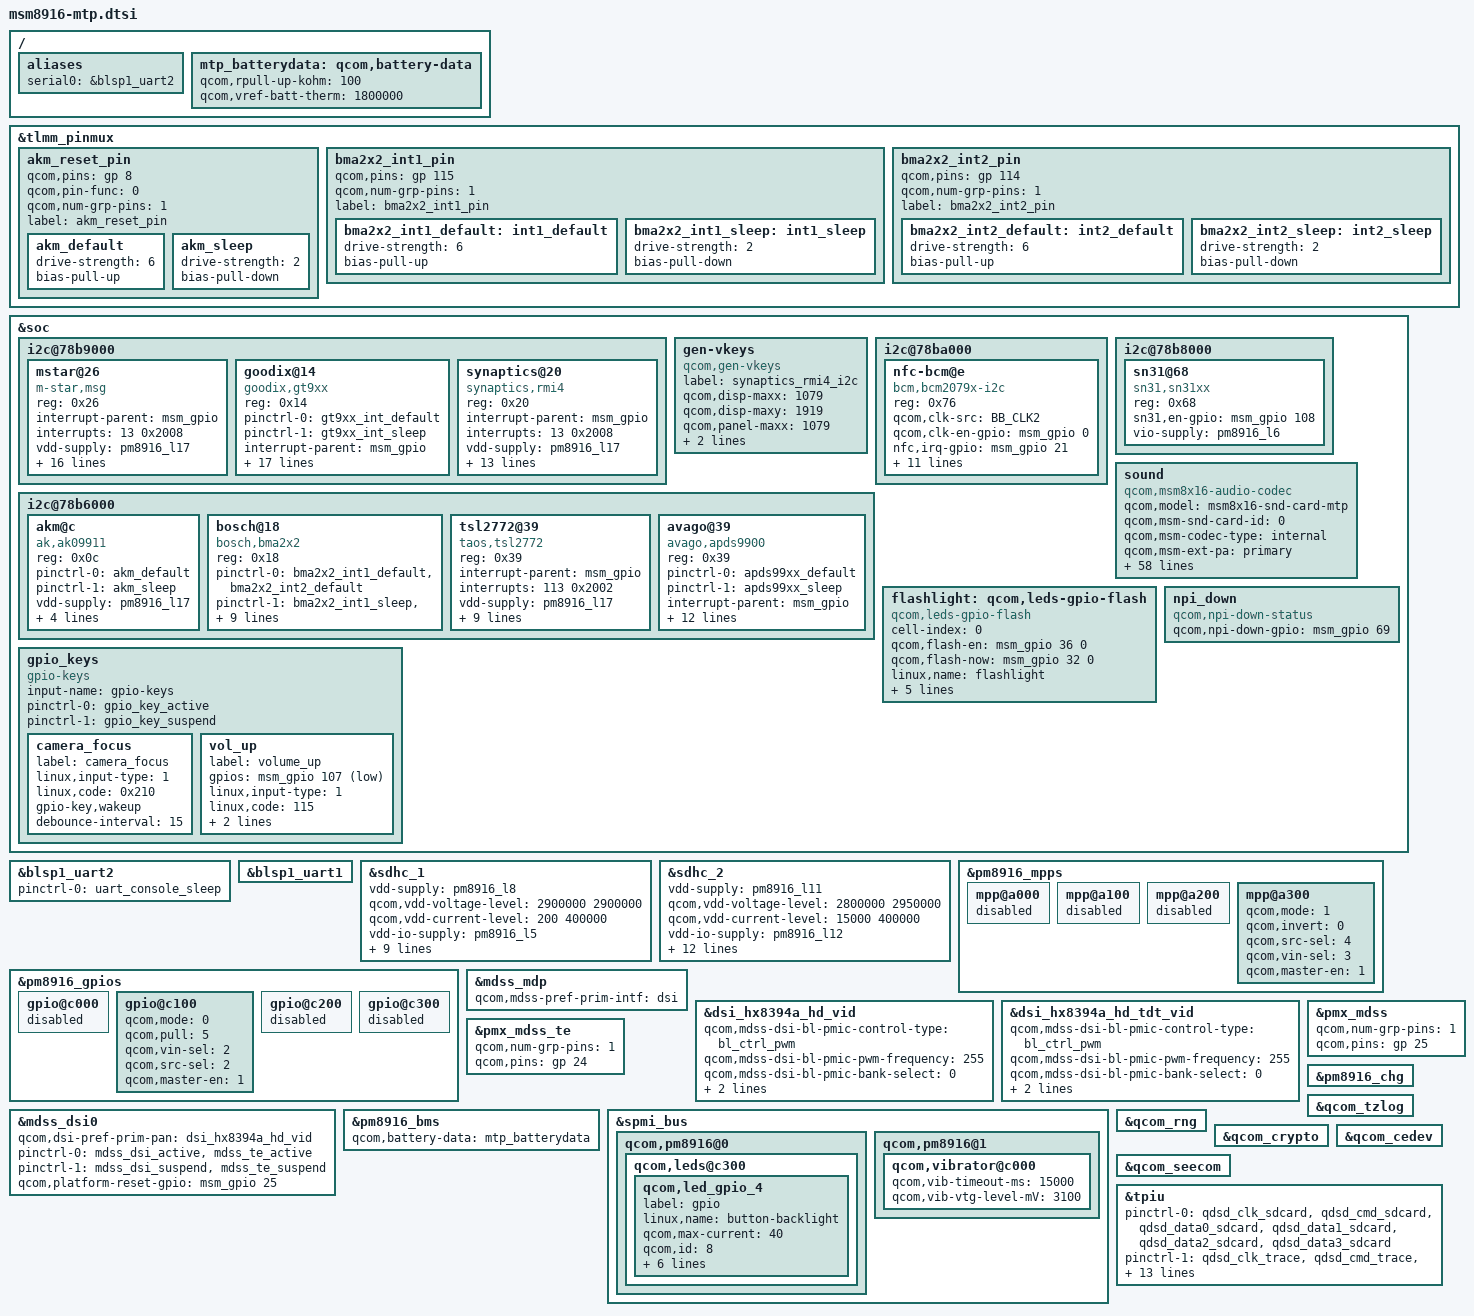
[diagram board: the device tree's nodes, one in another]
/* Copyright (c) 2014, The Linux Foundation. All rights reserved.
 *
 * This program is free software; you can redistribute it and/or modify
 * it under the terms of the GNU General Public License version 2 and
 * only version 2 as published by the Free Software Foundation.
 *
 * This program is distributed in the hope that it will be useful,
 * but WITHOUT ANY WARRANTY; without even the implied warranty of
 * MERCHANTABILITY or FITNESS FOR A PARTICULAR PURPOSE.  See the
 * GNU General Public License for more details.
 */

#include "msm8916.dtsi"
#include "msm8916-pinctrl.dtsi"
#include "msm8916-camera-sensor-mtp.dtsi"

/ {
	aliases {
		serial0 = &blsp1_uart2;
	};
};

/*  [Bug SW.Alto5_Global 724579 ] modify by xcb 2014-07-22 */
&tlmm_pinmux {
	akm_reset_pin {
		qcom,pins = <&gp 8>;
		qcom,pin-func = <0>;
		qcom,num-grp-pins = <1>;
		label = "akm_reset_pin";
		akm_default: akm_default {
			drive-strength = <6>;
			bias-pull-up;
		};
		akm_sleep: akm_sleep {
			drive-strength = <2>;
			bias-pull-down;
		};
	};


	bma2x2_int1_pin {
		qcom,pins = <&gp 115>;
		qcom,num-grp-pins = <1>;
		label = "bma2x2_int1_pin";
		bma2x2_int1_default: int1_default {
			  drive-strength = <6>;
			  bias-pull-up;
		};
		bma2x2_int1_sleep: int1_sleep {
			  drive-strength = <2>;
			  bias-pull-down;
		};
	};

	bma2x2_int2_pin {
		qcom,pins = <&gp 114>;
		qcom,num-grp-pins = <1>;
		label = "bma2x2_int2_pin";
		bma2x2_int2_default: int2_default {
			  drive-strength = <6>;
			  bias-pull-up;
		};
		bma2x2_int2_sleep: int2_sleep {
			  drive-strength = <2>;
			  bias-pull-down;
		};
	};
};
&soc {
	i2c@78b9000 { /* BLSP1 QUP5 */
	mstar@26{
			compatible = "m-star,msg";
			reg = <0x26>;
			interrupt-parent = <&msm_gpio>;
			interrupts = <13 0x2008>;
			vdd-supply = <&pm8916_l17>;
			vcc_i2c-supply = <&pm8916_l6>;
						
			mstar,name = "Mstar-TS";			
/*modify(add) by junfeng.zhou.sz for [TP driver development (1st source)] with PR721418 begin . 20140714*/			
			mstar,reset-gpios = <&msm_gpio 12 0x00>;
			mstar,interrupt-gpios = <&msm_gpio 13 0x2008>;	
			mstar,panel-coords = <0 0 540 960>;
			mstar,display-coords = <0 0 480 854>;
			mstar,button-map= <158 102 139>;
			mstar,no-force-update;
			mstar,i2c-pull-up;
			mstar,family-id = <0x0>;	

			mstar,disp-maxx = <720>;
			mstar,disp-maxy = <1280>;
/*modify(add) by junfeng.zhou.sz for [TP driver development (1st source)] with PR721418 end . */
			mstar,pan-maxx = <541>;
			mstar,pan-maxy = <1060>;
			mstar,key-codes = <158 102 139>;
			mstar,y-offset = <0>;
			/*label = "ms-msg21xx,Mstar-TS";*/
		};
/*[PLATFORM]-Add-BEGIN by TCTNB.ZXZ, FR-788135, 2014/09/25 add for FT5436 TP driver*/
		goodix@14 {
			compatible = "goodix,gt9xx";
			reg = <0x14>;

			pinctrl-names = "gt9xx_int_default","gt9xx_int_suspend";
			pinctrl-0 = <&gt9xx_int_default>;
			pinctrl-1 = <&gt9xx_int_sleep>;

			interrupt-parent = <&msm_gpio>;
			interrupts = <13 0x2008>;
			reset-gpios = <&msm_gpio 12 0x00>;
			interrupt-gpios = <&msm_gpio 13 0x00>;
                        vcc_i2c-supply = <&pm8916_l6>;
			avdd-supply =<&pm8916_l17>;/* <&tp_power>;*/
                        vdd-supply = <&pm8916_l17>;
			goodix,panel-coords =<0 0 720 1400>;
			goodix,display-coords = <0 0 720 1280>;
			goodix,button-map= <158 102 139>;
                        regulator-min-microvolt = <2800000>;
                        regulator-max-microvolt = <2800000>;
			goodix,family-id = <0x0>;
                        goodix,i2c-pull-up;
                        /*baoming TP config,Id=1*/
                       /*Modify by TCTNB Tianhongwei update config, version v67*/
                      goodix,cfg-data0 = [
				43 D0 02 00 05 05 35 05 01 C5 28 18 46 2D 03 05 00 00 00 02 03 00 00 14 14 1B 14 8A 09 0B 62 00 29 07 40 08
				00 01 33 11 32 11 00 00 00 10 00 32 00 00 19 32 82 94 C5 02 00 00 00 04 C6 37 00 A5 42 00 85 50 00 6C 62 00
				59 76 00 59 10 30 50 00 F7 45 35 33 33 27 00 00 00 00 00 00 00 00 00 00 00 00 00 00 00 00 00 00 00 00 00 19
				00 00 46 00 02 04 06 08 0A 0C 0E 10 12 14 16 FF FF FF 00 00 00 00 00 00 00 00 00 00 00 00 00 00	00 00 22 21
				20 1F 1E 1D 1C 18 16 12 10 0F 0C 0A 08 06 04 02 00 FF FF FF FF FF FF FF 00 00 00 4F FF FF FF FF FF FF FF 4F
				FF FF FF FF 51 01
				];
		      goodix,glove-cfg-data1 = [
				43 D0 02 00 05 05 34 11 01 08 28 0F 55 3C 03 05 00 00 00 00 10 04 00 14 15 1E 14 8C 2E 0E 37 3A B8 08 B8 08
				00 84 34 1D 00 14 08 03 14 03 64 32 00 00 1B 23 5A 94 C0 02 00 00 77 04 A3 26 00 8F 2E 00 7E 38 00 71 44 00
				67 52 00 67 18 40 60 00 57 50 40 EE E0 27 00 01 11 03 3C 32 00 00 FF 7F 00 00 00 00 00 00 00 00 00 19 4B 3C
				32 00 00 00 02 04 06 08 0A 0C 0E 10 12 14 16 18 1A 1C 00 00 00 00 00 00 00 00 00 00 00 00 00 00 00 00 2A 29
				28 26 24 22 21 20 1F 1E 1D 1C 18 16 14 13 12 10 0F 0C 0A 08 06 04 02 00 00 00 00 00 00 00 00 00 00 00 00 00
				00 00 00 00 F9 01
			];

		};
/*[PLATFORM]-Add-BEGIN by TCTNB.ZXZ*/
		synaptics@20 {
			compatible = "synaptics,rmi4";
			reg = <0x20>;
			interrupt-parent = <&msm_gpio>;
			interrupts = <13 0x2008>;
			vdd-supply = <&pm8916_l17>;
			vcc_i2c-supply = <&pm8916_l6>;
			/* pins used by touchscreen */
			pinctrl-names = "pmx_ts_active","pmx_ts_suspend","pmx_ts_suspend";
			pinctrl-0 = <&ts_int_active &ts_reset_active>;
			pinctrl-1 = <&ts_int_suspend &ts_reset_suspend>;
			pinctrl-2 = <&ts_release>;
			synaptics,display-coords = <0 0 1079 1919>;
			synaptics,panel-coords = <0 0 1079 2084>;
			synaptics,irq-gpio = <&msm_gpio 13 0x2008>;
			synaptics,reset-gpio = <&msm_gpio 12 0x0>;
			synaptics,i2c-pull-up;
			synaptics,power-down;
			synaptics,disable-gpios;
			/* Underlying clocks used by secure touch */
			clocks = <&clock_gcc clk_gcc_blsp1_ahb_clk>,
			 <&clock_gcc clk_gcc_blsp1_qup5_i2c_apps_clk>;
			clock-names = "iface_clk", "core_clk";
		};
	};

	gen-vkeys {
		compatible = "qcom,gen-vkeys";
		label = "synaptics_rmi4_i2c";
		qcom,disp-maxx = <1079>;
		qcom,disp-maxy = <1919>;
		qcom,panel-maxx = <1079>;
		qcom,panel-maxy = <2084>;
		qcom,key-codes = <158 139 172 217>;
	};

	i2c@78ba000 { /* BLSP1 QUP6 */
		nfc-bcm@e {/*modify by jch for NFC driver development*/
			compatible = "bcm,bcm2079x-i2c";/*modify by jch for NFC driver development*/
			reg = <0x76>;/*modify by jch for NFC driver development*/
/*
			qcom,irq-gpio = <&msm_gpio 21 0x00>;
			qcom,dis-gpio = <&msm_gpio 20 0x00>;
*/
			qcom,clk-src = "BB_CLK2";/*modify by jch for NFC driver development*/
			qcom,clk-en-gpio = <&msm_gpio 0 0x00>;/*modify by jch for NFC driver development*/
/*begin add by jch for NFC driver development*/
                        nfc,irq-gpio = <&msm_gpio 21 0x00>;
			nfc,wake_gpio = <&msm_gpio 20 0x00>;
			nfc,en-gpio = <&msm_gpio 31 0x00>;
                        nfc,clk-gpio = <&pm8916_gpios 2 0>;
                        /*comment this for cannot find SIM Card issue*/
                        /*uim-supply = <&pm8916_l14>;*/
/*end add by jch for NFC driver development*/
			interrupt-parent = <&msm_gpio>;
			interrupts = <21 0>;
                        vi2c-supply = <&pm8916_l5>;/*add by jch for NFC driver development*/
			interrupt-names = "nfc_irq";
			pinctrl-names = "nfc_active","nfc_suspend";
			pinctrl-0 = <&nfc_int_active &nfc_disable_active>;
			pinctrl-1 = <&nfc_int_suspend &nfc_disable_suspend>;
			qcom,clk-gpio = <&pm8916_gpios 2 0>;/* [BUFFIX]-Mod- by TCTNB.XQJ, PR-804255, 2014/10/29,add nfc clock control*/
			clocks = <&clock_rpm clk_bb_clk2_pin>;
			clock-names = "ref_clk";
		};
	};

	i2c@78b6000 { /* BLSP1 QUP2 */
		akm@c {
			compatible = "ak,ak09911";
			reg = <0x0c>;
			pinctrl-names = "default","sleep";
			pinctrl-0 = <&akm_default>;
			pinctrl-1 = <&akm_sleep>;
			vdd-supply = <&pm8916_l17>;
			vio-supply = <&pm8916_l6>;
			akm,layout = <0x3>;
			akm,gpio_rstn = <&msm_gpio 8 0x0>;
			akm,auto-report;
		};
	    bosch@18 { /* Accelerometer sensor [Bug SW.Alto5_Global 724579 ] modify by xcb 2014-07-22 */
	        compatible = "bosch,bma2x2";
	        reg = <0x18>;
	        pinctrl-names = "bma_default","bma_sleep";
	        pinctrl-0 = <&bma2x2_int1_default &bma2x2_int2_default>;
	        pinctrl-1 = <&bma2x2_int1_sleep &bma2x2_int2_sleep>;
	        interrupt-parent = <&msm_gpio>;
	        interrupts = <115 0x2002>;
	        vdd-supply = <&pm8916_l6>;
	        vio-supply = <&pm8916_l6>;
	        bosch,init-interval = <200>;
	        bosch,place = <2>;
	        bosch,gpio-int1 = <&msm_gpio 115 0x2002>;
	        bosch,gpio-int2 = <&msm_gpio 114 0x2002>;
	    };

		/*yongzhong.cheng,2014/07/24,PR 724584: add proximity and light sensor config begin*/
                tsl2772@39 {
                    compatible = "taos,tsl2772";
                        reg = <0x39>;
                        interrupt-parent = <&msm_gpio>;
                        interrupts = <113 0x2002>;
                        vdd-supply = <&pm8916_l17>;
                        vio-supply = <&pm8916_l6>;
                        tsl,irq-gpio = <&msm_gpio 113 0x2002>;
                        tsl,als-gate = <10>;    //
                        tsl,als-gain = <8>;     //
			tsl,control-reg = <0x25>; /* [BUFFIX]-Mod- by TCTNB.XQJ, PR-804886, 2014/10/23, p sensor debug*/
			tsl,wait-reg = <0x00>;
			tsl,ps-thdh = <950>;
			tsl,ps-thdl = <900>;
			tsl,ps-ppcount = <16>; /* [BUFFIX]-Mod- by yuzhong.li@tcl.com, PR-929456, 2015/3/2, p sensor debug*/
		};
                /*yongzhong.cheng,2014/07/24,PR 724584: add proximity and light sensor config end*/
		avago@39 { /* Ambient light and proximity sensor */
			compatible = "avago,apds9900";
			reg = <0x39>;
			pinctrl-names = "default","sleep";
			pinctrl-0 = <&apds99xx_default>;
			pinctrl-1 = <&apds99xx_sleep>;
			interrupt-parent = <&msm_gpio>;
			interrupts = <113 0x2002>;
			vdd-supply = <&pm8916_l17>;
			vio-supply = <&pm8916_l6>;
			avago,irq-gpio = <&msm_gpio 113 0x2002>;
			avago,ps-threshold = <600>;
			avago,ps-hysteresis-threshold = <500>;
			avago,ps-pulse = <8>;
			avago,ps-pgain = <0>;
			avago,als-B = <223>;
			avago,als-C = <70>;
			avago,als-D = <142>;
			avago,ga-value = <48>;
		};


	};
/* [PLATFORM]-Add-BEGIN by TCTNB.FLF, RR-813549, 2014/10/18, add sn31 for alto5 global */
	i2c@78b8000 { /* BLSP1 QUP2 */
        sn31@68{
              compatible = "sn31,sn31xx";
              reg = <0x68>;
              //pinctrl-names = "default";
              sn31,en-gpio = <&msm_gpio 108 0x00>; /*[BUGFIX]-add  by TCTNB.XQJ,PR-803287 2014/10/23,add  led ic sn31xx,gpio is used for led ic*/
              vio-supply = <&pm8916_l6>;
		};
	};
/* [PLATFORM]-Add-END by TCTNB.FLF */

	sound {
		compatible = "qcom,msm8x16-audio-codec";
		qcom,model = "msm8x16-snd-card-mtp";
		qcom,msm-snd-card-id = <0>;
		qcom,msm-codec-type = "internal";
		qcom,msm-ext-pa = "primary";
		qcom,msm-mclk-freq = <9600000>;
/* [PLATFORM]-Mod-BEGIN by TCTNB.HJ, 2014/10/17*/
		qcom,msm-mbhc-hphl-swh = <1>;
/* [PLATFORM]-Mod-END by TCTNB.HJ, 2014/10/17*/
		qcom,msm-mbhc-gnd-swh = <0>;
		qcom,msm-micbias1-ext-cap;
		qcom,msm-hs-micbias-type = "internal";
		qcom,audio-routing =
			"RX_BIAS", "MCLK",
			"SPK_RX_BIAS", "MCLK",
			"INT_LDO_H", "MCLK",
			"MIC BIAS External", "Handset Mic",
			"MIC BIAS Internal2", "Headset Mic",
			"MIC BIAS External", "Secondary Mic",
			"AMIC1", "MIC BIAS External",
			"AMIC2", "MIC BIAS Internal2",
			"AMIC3", "MIC BIAS External",
			"DMIC1", "MIC BIAS Internal1",
			"MIC BIAS Internal1", "Digital Mic1",
			"DMIC2", "MIC BIAS Internal1",
			"MIC BIAS Internal1", "Digital Mic2";
		pinctrl-names = "cdc_lines_act",
				"cdc_lines_sus",
				"cdc_lines_sec_ext_act",
				"cdc_lines_sec_ext_sus",
				"cross_conn_det_act",
				"cross_conn_det_sus";
		pinctrl-0 = <&cdc_pdm_lines_act>;
		pinctrl-1 = <&cdc_pdm_lines_sus>;
		pinctrl-2 = <&cdc_pdm_lines_act &cdc_ext_pa_act
						&cdc_ext_pa_ws_act>;
		pinctrl-3 = <&cdc_pdm_lines_sus &cdc_ext_pa_sus
						&cdc_ext_pa_ws_sus>;
		pinctrl-4 = <&cross_conn_det_act>;
		pinctrl-5 = <&cross_conn_det_sus>;
		qcom,cdc-us-euro-gpios = <&msm_gpio 120 0>;
		asoc-platform = <&pcm0>, <&pcm1>, <&voip>, <&voice>,
				<&loopback>, <&compress>, <&hostless>,
				<&afe>, <&lsm>, <&routing>, <&lpa>;
		asoc-platform-names = "msm-pcm-dsp.0", "msm-pcm-dsp.1",
				"msm-voip-dsp", "msm-pcm-voice", "msm-pcm-loopback",
				"msm-compress-dsp", "msm-pcm-hostless", "msm-pcm-afe",
				"msm-lsm-client", "msm-pcm-routing", "msm-pcm-lpa";
		asoc-cpu = <&dai_pri_auxpcm>, <&dai_hdmi>,
				<&dai_mi2s0>, <&dai_mi2s1>, <&dai_mi2s2>, <&dai_mi2s3>,
				<&sb_0_rx>, <&sb_0_tx>, <&sb_1_rx>, <&sb_1_tx>,
				<&sb_3_rx>, <&sb_3_tx>, <&sb_4_rx>, <&sb_4_tx>,
				<&bt_sco_rx>, <&bt_sco_tx>, <&int_fm_rx>, <&int_fm_tx>,
				<&afe_pcm_rx>, <&afe_pcm_tx>, <&afe_proxy_rx>, <&afe_proxy_tx>,
				<&incall_record_rx>, <&incall_record_tx>, <&incall_music_rx>,
				<&incall_music_2_rx>;
		asoc-cpu-names = "msm-dai-q6-auxpcm.1", "msm-dai-q6-hdmi.8",
				"msm-dai-q6-mi2s.0", "msm-dai-q6-mi2s.1",
				"msm-dai-q6-mi2s.2", "msm-dai-q6-mi2s.3",
				"msm-dai-q6-dev.16384", "msm-dai-q6-dev.16385",
				"msm-dai-q6-dev.16386", "msm-dai-q6-dev.16387",
				"msm-dai-q6-dev.16390", "msm-dai-q6-dev.16391",
				"msm-dai-q6-dev.16392", "msm-dai-q6-dev.16393",
				"msm-dai-q6-dev.12288", "msm-dai-q6-dev.12289",
				"msm-dai-q6-dev.12292", "msm-dai-q6-dev.12293",
				"msm-dai-q6-dev.224", "msm-dai-q6-dev.225",
				"msm-dai-q6-dev.241", "msm-dai-q6-dev.240",
				"msm-dai-q6-dev.32771", "msm-dai-q6-dev.32772",
				"msm-dai-q6-dev.32773", "msm-dai-q6-dev.32770";
		asoc-codec = <&stub_codec>, <&pm8916_tombak_dig>;
		asoc-codec-names = "msm-stub-codec.1", "tombak_codec";
	};
};

&blsp1_uart2 {
	status = "ok";
	pinctrl-names = "default";
	pinctrl-0 = <&uart_console_sleep>;
};

&soc {

	flashlight: qcom,leds-gpio-flash{
		cell-index = <0>;
		compatible = "qcom,leds-gpio-flash";
		status = "okay";
		qcom,flash-en = <&msm_gpio 36 0>;
		qcom,flash-now = <&msm_gpio 32 0>;
		linux,name = "flashlight";
		linux,default-trigger = "flashlight-trigger";
		qcom,current = <255>;
/* [PLATFORM]-Add-BEGIN by TCTNB.qijiang.yu, 2014/05/13, flash enable use gp_clk */
		clocks = <&clock_gcc clk_gcc_camss_gp1_clk>;
		clock-names = "cam_sensor_flash";

		pinctrl-names = "default", "sleep";
/*
		pinctrl-0 = <&ice40_infrared_default>;
		pinctrl-1 = <&ice40_infrared_sleep>;
*/
		pinctrl-0 = <&cam_sensor_flash_default>;
		pinctrl-1 = <&cam_sensor_flash_sleep>;
/* [PLATFORM]-Add-END by TCTNB.qijiang.yu */
	};
/* [PLATFORM]-Add-END by TCTNB.Alvin */
	gpio_keys {
		compatible = "gpio-keys";
		input-name = "gpio-keys";
		pinctrl-names = "tlmm_gpio_key_active","tlmm_gpio_key_suspend";
		pinctrl-0 = <&gpio_key_active>;
		pinctrl-1 = <&gpio_key_suspend>;

		camera_focus {
			label = "camera_focus";
			//gpios = <&msm_gpio 108 0x1>;/*[BUGFIX]-del   by TCTNB.XQJ,PR-803287 2014/10/23,add 2nd led ic sn31xx,gpio is used for led ic*/
			linux,input-type = <1>;
			linux,code = <0x210>;
			gpio-key,wakeup;
			debounce-interval = <15>;
		};
/*
		camera_snapshot {
			label = "camera_snapshot";
			gpios = <&msm_gpio 109 0x1>;
			linux,input-type = <1>;
			linux,code = <0x2fe>;
			gpio-key,wakeup;
			debounce-interval = <15>;
		};
*/
		vol_up {
			label = "volume_up";
			gpios = <&msm_gpio 107 0x1>;
			linux,input-type = <1>;
			linux,code = <115>;
			gpio-key,wakeup;
			debounce-interval = <15>;
		};
	};
/* [PLATFORM]-Add-BEGIN by TCTNB.ZXZ, 2014/12/13,FR853499 add for npi down status gpio */
	npi_down{
			compatible = "qcom,npi-down-status";
			qcom,npi-down-gpio = <&msm_gpio 69 0>;
		};
/* [PLATFORM]-Add-END by TCTNB.ZXZ */
};

&blsp1_uart1 {
	status = "ok";
};

&sdhc_1 {
	vdd-supply = <&pm8916_l8>;
	qcom,vdd-voltage-level = <2900000 2900000>;
	qcom,vdd-current-level = <200 400000>;

	vdd-io-supply = <&pm8916_l5>;
	qcom,vdd-io-always-on;
	qcom,vdd-io-lpm-sup;
	qcom,vdd-io-voltage-level = <1800000 1800000>;
	qcom,vdd-io-current-level = <200 60000>;

	pinctrl-names = "active", "sleep";
	pinctrl-0 = <&sdc1_clk_on &sdc1_cmd_on &sdc1_data_on>;
	pinctrl-1 = <&sdc1_clk_off &sdc1_cmd_off &sdc1_data_off>;

	qcom,nonremovable;

	status = "ok";
};

&sdhc_2 {
	vdd-supply = <&pm8916_l11>;
	qcom,vdd-voltage-level = <2800000 2950000>;
	qcom,vdd-current-level = <15000 400000>;

	vdd-io-supply = <&pm8916_l12>;
	qcom,vdd-io-voltage-level = <1800000 2950000>;
	qcom,vdd-io-current-level = <200 50000>;

	pinctrl-names = "active", "sleep";
	pinctrl-0 = <&sdc2_clk_on &sdc2_cmd_on &sdc2_data_on &sdc2_cd_on>;
	pinctrl-1 = <&sdc2_clk_off &sdc2_cmd_off &sdc2_data_off &sdc2_cd_off>;

	#address-cells = <0>;
	interrupt-parent = <&sdhc_2>;
	interrupts = <0 1 2>;
	#interrupt-cells = <1>;
	interrupt-map-mask = <0xffffffff>;
	interrupt-map = <0 &intc 0 125 0
			1 &intc 0 221 0
			2 &msm_gpio 38 0>;
	interrupt-names = "hc_irq", "pwr_irq", "status_irq";
	cd-gpios = <&msm_gpio 38 0x0>;  /* modify by shenghua.gong@tcl.com for sd card detect */

	status = "ok";
};

&pm8916_mpps {
	mpp@a000 { /* MPP 1 */
		/* VDD_PX */
		status = "disabled";
	};

	mpp@a100 { /* MPP 2 */
		/* HR LED */
		status = "disabled";
	};

	mpp@a200 { /* MPP 3 */
		/* VREF DAC */
		status = "disabled";
	};

	mpp@a300 { /* MPP 4 */
		/* Backlight PWM */
		qcom,mode = <1>;		/* Digital output */
		qcom,invert = <0>;		/* Disable invert */
		qcom,src-sel = <4>;		/* DTEST1 */
		qcom,vin-sel = <3>;		/* VPH_PWR */
		qcom,master-en = <1>;		/* Enable MPP */
	};
};

&pm8916_gpios {
	gpio@c000 { /* GPIO 1 */
		/* Battery UICC Alarm */
		status = "disabled";
	};

	gpio@c100 { /* GPIO 2 */
		/* NFC_CLK_REQ */
		qcom,mode = <0>; /* QPNP_PIN_MODE_DIG_IN */
		qcom,pull = <5>; /* QPNP_PIN_PULL_NO */
		qcom,vin-sel = <2>; /* QPNP_PIN_VIN2 */
		qcom,src-sel = <2>; /* QPNP_PIN_SEL_FUNC_1 */
		qcom,master-en = <1>;
	};

	gpio@c200 { /* GPIO 3 */
		/* External regulator control for WTR */
		status = "disabled";
	};

	gpio@c300 { /* GPIO 4 */
		/* External regulator control for APC */
		status = "disabled";
	};
};

/* [PLATFORM] TCTNB.THW, FR-623588, 2014/09/19, Alto5_VDF 1st lcd */
#include "dsi-panel-hx8394a-hd-truly-video.dtsi"
/* [PLATFORM] TCTNB.THW, FR-623588, 2014/09/23, Alto5_VDF 2st lcd */
#include "dsi-panel-hx8394a-hd-tdt-video.dtsi"

&mdss_mdp {
	qcom,mdss-pref-prim-intf = "dsi";
};

&dsi_hx8394a_hd_vid {
/* [PLATFORM]-Add-END by TCTNB.FLF */
	qcom,mdss-dsi-bl-pmic-control-type = "bl_ctrl_pwm";
	qcom,mdss-dsi-bl-pmic-pwm-frequency = <255>;
	qcom,mdss-dsi-bl-pmic-bank-select = <0>;
	qcom,mdss-dsi-pwm-gpio = <&pm8916_mpps 4 0>;
	qcom,cont-splash-enabled;
};

/* [PLATFORM] TCTNB.THW, FR-623588, 2014/09/23, Alto5_VDF 2st lcd */
&dsi_hx8394a_hd_tdt_vid {
	qcom,mdss-dsi-bl-pmic-control-type = "bl_ctrl_pwm";
 	qcom,mdss-dsi-bl-pmic-pwm-frequency = <255>;
 	qcom,mdss-dsi-bl-pmic-bank-select = <0>;
 	qcom,mdss-dsi-pwm-gpio = <&pm8916_mpps 4 0>;
 	qcom,cont-splash-enabled;
};
/*tianhongwei remove gpio cfg lcd not use   2014/10/24*/
&pmx_mdss {
	qcom,num-grp-pins = <1>;
	qcom,pins = <&gp 25>;
};

&pmx_mdss_te {
	qcom,num-grp-pins = <1>;
	qcom,pins = <&gp 24>;
};

&mdss_dsi0 {
	qcom,dsi-pref-prim-pan = <&dsi_hx8394a_hd_vid>;
	pinctrl-names = "mdss_default", "mdss_sleep";
	pinctrl-0 = <&mdss_dsi_active &mdss_te_active>;
	pinctrl-1 = <&mdss_dsi_suspend &mdss_te_suspend>;

/*tianhongwei remove gpio cfg lcd not use   2014/10/24*/
	qcom,platform-reset-gpio = <&msm_gpio 25 0>;
};

&dsi_hx8394a_hd_vid {
       qcom,cont-splash-enabled;
};

&pm8916_chg {
	status = "ok";
//	qcom,charging-disabled;
};

/ {
	mtp_batterydata: qcom,battery-data {
		qcom,rpull-up-kohm = <100>;
		qcom,vref-batt-therm = <1800000>;

/* [PLATFORM]-Add-BEGIN by TCTNB.FLF, PR-825941, PR-825993, 2014/11/03, add battery profile */
//		#include "batterydata-palladium.dtsi"
		#include "TCL_TLP025A1_1594286_2500mAh_VBMS_3p4COV_Final_BYD.dtsi"
		#include "TCL_TLp025A2_1594232_2520mAh_3p4COV_VBMS_Final_SCUD.dtsi"
/* [PLATFORM]-Add-END by TCTNB.FLF */
	};
};

&pm8916_bms {
	status = "ok";
	qcom,battery-data = <&mtp_batterydata>;
};

&spmi_bus {
	qcom,pm8916@0 {
/*[PLATFORM]-Mod-BEGIN by TCTNB.FLF, FR-816348, 2014/10/23, pmic gpio4 for button-bakclight */
/*
		qcom,leds@a100 {
			status = "okay";
			qcom,led_mpp_2 {
				label = "mpp";
				linux,name = "button-backlight";
				linux,default-trigger = "none";
				qcom,default-state = "off";
				qcom,max-current = <40>;
				qcom,current-setting = <5>;
				qcom,id = <6>;
				qcom,mode = "manual";
				qcom,source-sel = <1>;
				qcom,mode-ctrl = <0x60>;
			};
		};
*/
/*[PLATFORM]-Mod-BEGIN by TCTNB.ZXZ, PR-875948, 2014/12/17, change GPIO4 output voltage from 1.2 to 1.8 v (change vin-ctrl from 0x02 to 0x03) */
			qcom,leds@c300 {
			status = "okay";
			qcom,led_gpio_4 {
				label = "gpio";
				linux,name = "button-backlight";
				qcom,max-current = <40>;
				qcom,id = <8>;
				linux,default-trigger = "none";
				qcom,default-state = "off";
				qcom,current-setting = <5>;
				qcom,mode-ctrl = <0x10>;
				qcom,source-sel = <1>;
				qcom,vin-ctrl = <0x03>;
			};
		};
/*[PLATFORM]-Mod-END by TCTNB.FLF*/
	};
};

&qcom_tzlog {
	status = "okay";
};

&qcom_rng {
	status = "okay";
};

&qcom_crypto {
	status = "okay";
};

&qcom_cedev {
	status = "okay";
};

&qcom_seecom {
	status = "okay";
};

/* CoreSight */
&tpiu {
      pinctrl-names = "sdcard", "trace", "swduart",
		      "swdtrc", "jtag", "spmi";
       /* NIDnT */
      pinctrl-0 = <&qdsd_clk_sdcard &qdsd_cmd_sdcard
                  &qdsd_data0_sdcard &qdsd_data1_sdcard
                  &qdsd_data2_sdcard &qdsd_data3_sdcard>;
      pinctrl-1 = <&qdsd_clk_trace &qdsd_cmd_trace
                  &qdsd_data0_trace &qdsd_data1_trace
                  &qdsd_data2_trace &qdsd_data3_trace>;
      pinctrl-2 = <&qdsd_cmd_swduart &qdsd_data0_swduart
                  &qdsd_data1_swduart &qdsd_data2_swduart
                  &qdsd_data3_swduart>;
      pinctrl-3 = <&qdsd_clk_swdtrc &qdsd_cmd_swdtrc
                  &qdsd_data0_swdtrc &qdsd_data1_swdtrc
                  &qdsd_data2_swdtrc &qdsd_data3_swdtrc>;
      pinctrl-4 = <&qdsd_cmd_jtag &qdsd_data0_jtag
                  &qdsd_data1_jtag &qdsd_data2_jtag
                  &qdsd_data3_jtag>;
      pinctrl-5 = <&qdsd_clk_spmi &qdsd_cmd_spmi
                  &qdsd_data0_spmi &qdsd_data3_spmi>;
};

&spmi_bus {
	qcom,pm8916@1 {
		qcom,vibrator@c000 {
			status = "okay";
			qcom,vib-timeout-ms = <15000>;
			qcom,vib-vtg-level-mV = <3100>;
		};
	};
};
